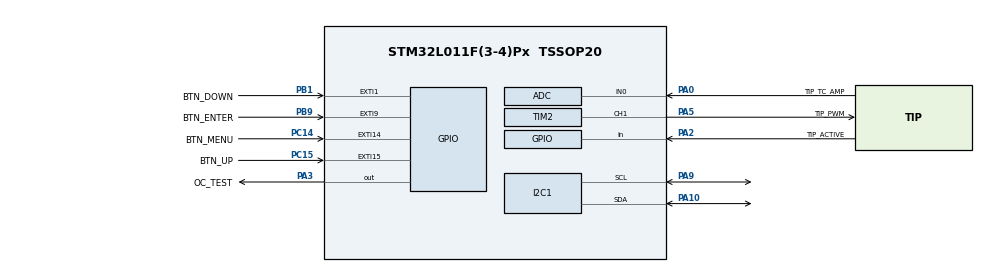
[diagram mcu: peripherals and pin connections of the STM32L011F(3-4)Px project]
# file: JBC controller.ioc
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ADC.ClockPrescaler=ADC_CLOCK_SYNC_PCLK_DIV4
ADC.EOCSelection=ADC_EOC_SINGLE_CONV
ADC.EnableAnalogWatchDog=false
ADC.OversamplingMode=ENABLE
ADC.Ratio=ADC_OVERSAMPLING_RATIO_16
ADC.RightBitShift=ADC_RIGHTBITSHIFT_4
ADC.SamplingTime=ADC_SAMPLETIME_160CYCLES_5
ADC.TriggeredMode=ADC_TRIGGEREDMODE_SINGLE_TRIGGER
Dma.ADC.0.Direction=DMA_PERIPH_TO_MEMORY
Dma.ADC.0.Instance=DMA1_Channel1
Dma.ADC.0.MemDataAlignment=DMA_MDATAALIGN_HALFWORD
Dma.ADC.0.MemInc=DMA_MINC_ENABLE
Dma.ADC.0.Mode=DMA_NORMAL
Dma.ADC.0.PeriphDataAlignment=DMA_PDATAALIGN_HALFWORD
Dma.ADC.0.PeriphInc=DMA_PINC_DISABLE
Dma.ADC.0.Priority=DMA_PRIORITY_LOW
Dma.Request0=ADC
I2C1.Timing=0x00707CBB
Mcu.Family=STM32L0
Mcu.Name=STM32L011F(3-4)Px
Mcu.Package=TSSOP20
NVIC.DMA1_Channel1_IRQn=true\:0\:0\:true\:false\:true\:false\:true\:true
NVIC.EXTI0_1_IRQn=true\:0\:0\:false\:false\:true\:true\:true\:true
NVIC.EXTI4_15_IRQn=true\:0\:0\:false\:false\:true\:true\:true\:true
NVIC.TIM2_IRQn=true\:0\:0\:false\:false\:true\:true\:true\:true
PA0-CK_IN.GPIO_Label=TIP_TC_AMP
PA0-CK_IN.Mode=IN0
PA0-CK_IN.Signal=ADC_IN0
PA1.GPIO_Label=HEATER_CURRENT_AMP
PA1.Signal=ADC_IN1
PA10.GPIO_Pu=GPIO_PULLUP
PA10.Mode=I2C
PA10.Signal=I2C1_SDA
PA13.Mode=Serial_Wire
PA13.Signal=SYS_SWDIO
PA14.Mode=Serial_Wire
PA14.Signal=SYS_SWCLK
PA2.GPIO_Label=TIP_ACTIVE
PA2.GPIO_PuPd=GPIO_PULLUP
PA2.Signal=GPIO_Input
PA3.GPIO_Label=OC_TEST
PA3.Signal=GPIO_Output
PA5.GPIO_Label=TIP_PWM
PA5.Signal=S_TIM2_CH1
PA9.GPIO_Pu=GPIO_PULLUP
PA9.Mode=I2C
PA9.Signal=I2C1_SCL
PB1.GPIO_Label=BTN_DOWN
PB1.GPIO_ModeDefaultEXTI=GPIO_MODE_IT_FALLING
PB1.GPIO_PuPd=GPIO_PULLUP
PB1.Signal=GPXTI1
PB9-BOOT0.GPIO_Label=BTN_ENTER
PB9-BOOT0.GPIO_ModeDefaultEXTI=GPIO_MODE_IT_FALLING
PB9-BOOT0.GPIO_PuPd=GPIO_PULLUP
PB9-BOOT0.Signal=GPXTI9
PC14-OSC32_IN.GPIO_Label=BTN_MENU
PC14-OSC32_IN.GPIO_ModeDefaultEXTI=GPIO_MODE_IT_FALLING
PC14-OSC32_IN.GPIO_PuPd=GPIO_PULLUP
PC14-OSC32_IN.Signal=GPXTI14
PC15-OSC32_OUT.GPIO_Label=BTN_UP
PC15-OSC32_OUT.GPIO_ModeDefaultEXTI=GPIO_MODE_IT_FALLING
PC15-OSC32_OUT.GPIO_PuPd=GPIO_PULLUP
PC15-OSC32_OUT.Signal=GPXTI15
ProjectManager.HeapSize=0x100
ProjectManager.StackSize=0x200
ProjectManager.TargetToolchain=STM32CubeIDE
RCC.AHBFreq_Value=32000000
RCC.APB1Freq_Value=32000000
RCC.APB1TimFreq_Value=32000000
RCC.APB2Freq_Value=32000000
RCC.APB2TimFreq_Value=32000000
RCC.HCLKFreq_Value=32000000
RCC.HSE_VALUE=8000000
RCC.HSI16_VALUE=16000000
RCC.HSI_VALUE=16000000
RCC.LSE_VALUE=32768
RCC.MSIClockRange=RCC_MSIRANGE_6
RCC.MSI_VALUE=4194000
RCC.PLLMUL=RCC_PLLMUL_4
RCC.SYSCLKFreq_VALUE=32000000
RCC.SYSCLKSource=RCC_SYSCLKSOURCE_PLLCLK
RCC.VCOOutputFreq_Value=64000000
SH.S_TIM2_CH1.0=TIM2_CH1,PWM Generation1 CH1
TIM2.Channel-Output\ Compare2\ No\ Output=TIM_CHANNEL_2
TIM2.Channel-PWM\ Generation1\ CH1=TIM_CHANNEL_1
TIM2.OCMode_2=TIM_OCMODE_ACTIVE
TIM2.OCPolarity_1=TIM_OCPOLARITY_HIGH
TIM2.OCPolarity_2=TIM_OCPOLARITY_HIGH
TIM2.Period=999
TIM2.Prescaler=31
TIM2.Pulse-Output\ Compare2\ No\ Output=0
TIM2.Pulse-PWM\ Generation1\ CH1=0
VP_TIM2_VS_ClockSourceINT.Mode=Internal
VP_TIM2_VS_no_output2.Mode=Output Compare2 No Output
board=custom

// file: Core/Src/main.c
/* USER CODE BEGIN Header */
/**
  ******************************************************************************
  * @file           : main.c
  * @brief          : Main program body
  ******************************************************************************
  * @attention
  *
  * <h2><center>&copy; Copyright (c) 2021 STMicroelectronics.
  * All rights reserved.</center></h2>
  *
  * This software component is licensed by ST under BSD 3-Clause license,
  * the "License"; You may not use this file except in compliance with the
  * License. You may obtain a copy of the License at:
  *                        opensource.org/licenses/BSD-3-Clause
  *
  ******************************************************************************
  */
/* USER CODE END Header */
#include "main.h"
#include "adc.h"
#include "dma.h"
#include "i2c.h"
#include "tim.h"
#include "gpio.h"

/* USER CODE BEGIN Includes */
#include "user_main.h"
#include "lcd_hd44780_i2c.h"
/* USER CODE END Includes */

void SystemClock_Config(void);

int main(void)
{

  /* MCU Configuration--------------------------------------------------------*/

  /* Reset of all peripherals, Initializes the Flash interface and the Systick. */
  HAL_Init();

  /* Configure the system clock */
  SystemClock_Config();

  /* Initialize all configured peripherals */
  MX_GPIO_Init();
  MX_DMA_Init();
  MX_ADC_Init();
  MX_I2C1_Init();
  MX_TIM2_Init();
  /* USER CODE BEGIN 2 */
  user_main();
  /* USER CODE END 2 */

  /* Infinite loop */
  while (1)
  {

  }
}

void SystemClock_Config(void)
{
  LL_FLASH_SetLatency(LL_FLASH_LATENCY_1);
  while(LL_FLASH_GetLatency()!= LL_FLASH_LATENCY_1)
  {
  }
  LL_PWR_SetRegulVoltageScaling(LL_PWR_REGU_VOLTAGE_SCALE1);
  while (LL_PWR_IsActiveFlag_VOS() != 0)
  {
  }
  LL_RCC_HSI_Enable();

   /* Wait till HSI is ready */
  while(LL_RCC_HSI_IsReady() != 1)
  {

  }
  LL_RCC_HSI_SetCalibTrimming(16);
  LL_RCC_PLL_ConfigDomain_SYS(LL_RCC_PLLSOURCE_HSI, LL_RCC_PLL_MUL_4, LL_RCC_PLL_DIV_2);
  LL_RCC_PLL_Enable();

   /* Wait till PLL is ready */
  while(LL_RCC_PLL_IsReady() != 1)
  {

  }
  LL_RCC_SetAHBPrescaler(LL_RCC_SYSCLK_DIV_1);
  LL_RCC_SetAPB1Prescaler(LL_RCC_APB1_DIV_1);
  LL_RCC_SetAPB2Prescaler(LL_RCC_APB2_DIV_1);
  LL_RCC_SetSysClkSource(LL_RCC_SYS_CLKSOURCE_PLL);

   /* Wait till System clock is ready */
  while(LL_RCC_GetSysClkSource() != LL_RCC_SYS_CLKSOURCE_STATUS_PLL)
  {

  }
  LL_SetSystemCoreClock(32000000);

   /* Update the time base */
  if (HAL_InitTick (TICK_INT_PRIORITY) != HAL_OK)
  {
    Error_Handler();
  }
  LL_RCC_SetI2CClockSource(LL_RCC_I2C1_CLKSOURCE_PCLK1);
}

void Error_Handler(void)
{
  /* USER CODE BEGIN Error_Handler_Debug */

	__disable_irq();
	// Disable tip PWM
	__HAL_TIM_SET_COMPARE(&htim2, TIM_CHANNEL_1, 0);

	lcdSetCursorPosition(0, 0);
	lcdPrintStr("ErrorHandler:   ");

	while (1);

  /* USER CODE END Error_Handler_Debug */
}
